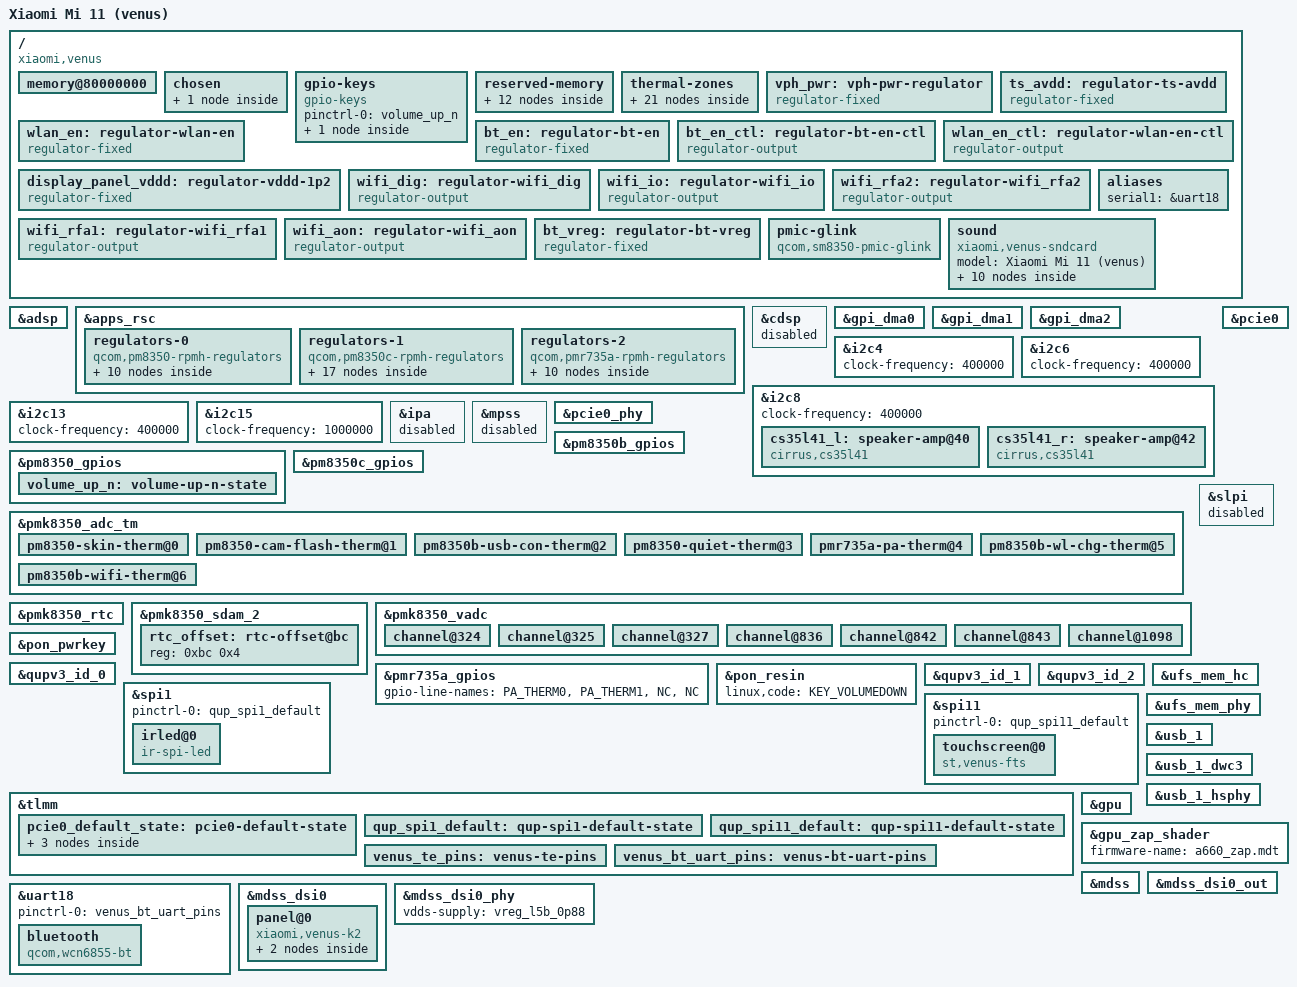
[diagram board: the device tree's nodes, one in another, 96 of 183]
// SPDX-License-Identifier: BSD-3-Clause
/*
 * Copyright (c) 2023, Xilin Wu <wuxilin123@gmail.com>
 */

/dts-v1/;

#include <dt-bindings/regulator/qcom,rpmh-regulator.h>
#include <dt-bindings/iio/qcom,spmi-adc7-pm8350.h>
#include <dt-bindings/iio/qcom,spmi-adc7-pm8350b.h>
#include <dt-bindings/iio/qcom,spmi-adc7-pmk8350.h>
#include <dt-bindings/iio/qcom,spmi-adc7-pmr735a.h>
#include "sm8350.dtsi"
#include "pm8350.dtsi"
#include "pm8350b.dtsi"
#include "pm8350c.dtsi"
#include "pmk8350.dtsi"
#include "pmr735a.dtsi"

/*
 * Delete following upstream (sm8350.dtsi) reserved
 * memory mappings which are different on this device.
 */
/delete-node/ &pil_adsp_mem;
/delete-node/ &pil_slpi_mem;
/delete-node/ &pil_cdsp_mem;
/delete-node/ &pil_ipa_fw_mem;
/delete-node/ &pil_ipa_gsi_mem;
/delete-node/ &pil_gpu_mem;
/delete-node/ &pil_spss_mem;
/delete-node/ &pil_modem_mem;
/delete-node/ &rmtfs_mem;
/delete-node/ &pil_trustedvm_mem;
/delete-node/ &removed_mem;

/ {
	model = "Xiaomi Mi 11 (venus)";
	compatible = "xiaomi,venus", "qcom,sm8350";

	/* ABL 挑表项用; 实测值来自本机 Android 的 /sys/firmware/fdt */
	qcom,msm-id = <0x19f 0x20001>, <0x1c8 0x20001>, <0x1f5 0x20001>;
	qcom,board-id = <0x10008 0x0>;
	chassis-type = "handset";

	/* 本机实测(Android /sys/firmware/fdt): 8GB */
	memory@80000000 {
		device_type = "memory";
		reg = <0x00 0x80000000 0x00 0x39700000>,
		      <0x01 0x80000000 0x01 0x00000000>,
		      <0x00 0xc0000000 0x00 0xc0000000>;
	};

	chosen {
		#address-cells = <2>;
		#size-cells = <2>;
		ranges;

		/* 复用 ABL 摆好的 splash 帧缓冲, 靠 simpledrm 把早期 dmesg/panic 打到屏幕上;
		 * 不涉及面板/DSI 驱动 */
		framebuffer0: framebuffer@e1000000 {
			compatible = "simple-framebuffer";
			reg = <0 0xe1000000 0 (1440 * 3200 * 4)>;
			width = <1440>;
			height = <3200>;
			stride = <(1440 * 4)>;
			format = "a8r8g8b8";
		};

	};

	gpio-keys {
		compatible = "gpio-keys";

		pinctrl-0 = <&volume_up_n>;
		pinctrl-names = "default";

		key-volume-up {
			label = "Volume Up";
			linux,code = <KEY_VOLUMEUP>;
			gpios = <&pm8350_gpios 6 GPIO_ACTIVE_LOW>;
			debounce-interval = <15>;
			linux,can-disable;
			wakeup-source;
		};
	};


	reserved-memory {
		/* venus 的 ABL splash 区 */
		cont_splash_mem: memory@e1000000 {
			reg = <0 0xe1000000 0 0x2300000>;
			no-map;
		};

		pil_adsp_mem: memory@86100000 {
			reg = <0 0x86100000 0 0x3900000>;
			no-map;
		};

		pil_slpi_mem: memory@89a00000 {
			reg = <0 0x89a00000 0 0x2f00000>;
			no-map;
		};

		pil_cdsp_mem: memory@8c900000 {
			reg = <0 0x8c900000 0 0x1e00000>;
			no-map;
		};

		pil_ipa_fw_mem: memory@8e700000 {
			reg = <0 0x8e700000 0 0x10000>;
			no-map;
		};

		pil_ipa_gsi_mem: memory@8e710000 {
			reg = <0 0x8e710000 0 0xa000>;
			no-map;
		};

		pil_gpu_mem: memory@8e71a000 {
			reg = <0 0x8e71a000 0 0x2000>;
			no-map;
		};

		pil_spss_mem: memory@8e800000 {
			reg = <0 0x8e800000 0 0x100000>;
			no-map;
		};

		pil_modem_mem: memory@8f000000 {
			reg = <0 0x8f000000 0 0x10000000>;
			no-map;
		};

		/* venus 的真实 ramoops 区(取自本机下游 DTB: reg=<0xa9000000 0x200000>,
		 * pmsg-size 占满整块)。声明成 console 区, panic 日志落在偏移 0,
		 * Android 的 /dev/pmsg0 正好映射到同一位置 */
		ramoops@a9000000 {
			compatible = "ramoops";
			reg = <0 0xa9000000 0 0x200000>;
			console-size = <0x200000>;
			no-map;
		};


		rmtfs_mem: memory@d6a00000 {
			compatible = "qcom,rmtfs-mem";
			reg = <0 0xd6a00000 0 0x300000>;
			no-map;

			qcom,client-id = <1>;
			qcom,vmid = <15>;
		};

		removed_mem: memory@d8800000 {
			reg = <0 0xd8800000 0 0x8800000>;
			no-map;
		};

	};

	thermal-zones {
		skin-thermal {
			polling-delay-passive = <0>;
			polling-delay = <0>;
			thermal-sensors = <&pmk8350_adc_tm 0>;

			trips {
				active-config0 {
					temperature = <125000>;
					hysteresis = <1000>;
					type = "passive";
				};
			};
		};

		flash-thermal {
			polling-delay-passive = <0>;
			polling-delay = <0>;
			thermal-sensors = <&pmk8350_adc_tm 1>;

			trips {
				active-config0 {
					temperature = <125000>;
					hysteresis = <1000>;
					type = "passive";
				};
			};
		};

		usb-con-thermal {
			polling-delay-passive = <0>;
			polling-delay = <0>;
			thermal-sensors = <&pmk8350_adc_tm 2>;

			trips {
				active-config0 {
					temperature = <125000>;
					hysteresis = <1000>;
					type = "passive";
				};
			};
		};

		quiet-thermal {
			polling-delay-passive = <0>;
			polling-delay = <0>;
			thermal-sensors = <&pmk8350_adc_tm 3>;

			trips {
				active-config0 {
					temperature = <125000>;
					hysteresis = <1000>;
					type = "passive";
				};
			};
		};

		pa-thermal {
			polling-delay-passive = <0>;
			polling-delay = <0>;
			thermal-sensors = <&pmk8350_adc_tm 4>;

			trips {
				active-config0 {
					temperature = <125000>;
					hysteresis = <1000>;
					type = "passive";
				};
			};
		};

		wl-chg-thermal {
			polling-delay-passive = <0>;
			polling-delay = <0>;
			thermal-sensors = <&pmk8350_adc_tm 5>;

			trips {
				active-config0 {
					temperature = <125000>;
					hysteresis = <1000>;
					type = "passive";
				};
			};
		};

		wifi-thermal {
			polling-delay-passive = <0>;
			polling-delay = <0>;
			thermal-sensors = <&pmk8350_adc_tm 6>;

			trips {
				active-config0 {
					temperature = <125000>;
					hysteresis = <1000>;
					type = "passive";
				};
			};
		};
	};

	vph_pwr: vph-pwr-regulator {
		compatible = "regulator-fixed";
		regulator-name = "vph_pwr";
		regulator-min-microvolt = <3700000>;
		regulator-max-microvolt = <3700000>;

		regulator-always-on;
		regulator-boot-on;
	};
};

&adsp {
	firmware-name = "qcom/sm8350/xiaomi/venus/adsp.mdt";
	status = "okay";
};

&apps_rsc {
	regulators-0 {
		compatible = "qcom,pm8350-rpmh-regulators";
		qcom,pmic-id = "b";

		vdd-s1-supply = <&vph_pwr>;
		vdd-s2-supply = <&vph_pwr>;
		vdd-s3-supply = <&vph_pwr>;
		vdd-s4-supply = <&vph_pwr>;
		vdd-s5-supply = <&vph_pwr>;
		vdd-s6-supply = <&vph_pwr>;
		vdd-s7-supply = <&vph_pwr>;
		vdd-s8-supply = <&vph_pwr>;
		vdd-s9-supply = <&vph_pwr>;
		vdd-s10-supply = <&vph_pwr>;
		vdd-s11-supply = <&vph_pwr>;
		vdd-s12-supply = <&vph_pwr>;

		vdd-l1-l4-supply = <&vreg_s11b_0p95>;
		vdd-l2-l7-supply = <&vreg_bob>;
		vdd-l3-l5-supply = <&vreg_bob>;
		vdd-l6-l9-l10-supply = <&vreg_s11b_0p95>;
		vdd-l8-supply = <&vreg_s2c_0p8>;

		vreg_s10b_1p8: smps10 {
			regulator-name = "vreg_s10b_1p8";
			regulator-min-microvolt = <1800000>;
			regulator-max-microvolt = <1800000>;
		};

		vreg_s11b_0p95: smps11 {
			regulator-name = "vreg_s11b_0p95";
			regulator-min-microvolt = <752000>;
			regulator-max-microvolt = <752000>;
		};

		vreg_s12b_1p25: smps12 {
			regulator-name = "vreg_s12b_1p25";
			regulator-min-microvolt = <1352000>;
			regulator-max-microvolt = <1352000>;
		};

		vreg_l1b_0p88: ldo1 {
			regulator-name = "vreg_l1b_0p88";
			regulator-min-microvolt = <912000>;
			regulator-max-microvolt = <920000>;
			regulator-initial-mode = <RPMH_REGULATOR_MODE_HPM>;
		};

		vreg_l2b_3p07: ldo2 {
			regulator-name = "vreg_l2b_3p07";
			regulator-min-microvolt = <3072000>;
			regulator-max-microvolt = <3072000>;
			regulator-initial-mode = <RPMH_REGULATOR_MODE_HPM>;
		};

		vreg_l3b_0p9: ldo3 {
			regulator-name = "vreg_l3b_0p9";
			regulator-min-microvolt = <904000>;
			regulator-max-microvolt = <904000>;
			regulator-initial-mode = <RPMH_REGULATOR_MODE_HPM>;
		};

		vreg_l5b_0p88: ldo5 {
			regulator-name = "vreg_l5b_0p88";
			regulator-min-microvolt = <880000>;
			regulator-max-microvolt = <888000>;
			regulator-initial-mode = <RPMH_REGULATOR_MODE_HPM>;
		};

		vreg_l6b_1p2: ldo6 {
			regulator-name = "vreg_l6b_1p2";
			regulator-min-microvolt = <1200000>;
			regulator-max-microvolt = <1208000>;
			regulator-initial-mode = <RPMH_REGULATOR_MODE_HPM>;
		};

		vreg_l7b_2p96: ldo7 {
			regulator-name = "vreg_l7b_2p96";
			regulator-min-microvolt = <2400000>;
			regulator-max-microvolt = <3008000>;
			regulator-initial-mode = <RPMH_REGULATOR_MODE_HPM>;
		};

		vreg_l9b_1p2: ldo9 {
			regulator-name = "vreg_l9b_1p2";
			regulator-min-microvolt = <1200000>;
			regulator-max-microvolt = <1200000>;
			regulator-initial-mode = <RPMH_REGULATOR_MODE_HPM>;
		};
	};

	regulators-1 {
		compatible = "qcom,pm8350c-rpmh-regulators";
		qcom,pmic-id = "c";

		vdd-s1-supply = <&vph_pwr>;
		vdd-s2-supply = <&vph_pwr>;
		vdd-s3-supply = <&vph_pwr>;
		vdd-s4-supply = <&vph_pwr>;
		vdd-s5-supply = <&vph_pwr>;
		vdd-s6-supply = <&vph_pwr>;
		vdd-s7-supply = <&vph_pwr>;
		vdd-s8-supply = <&vph_pwr>;
		vdd-s9-supply = <&vph_pwr>;
		vdd-s10-supply = <&vph_pwr>;

		vdd-l1-l12-supply = <&vreg_s1c_1p86>;
		vdd-l2-l8-supply = <&vreg_s1c_1p86>;
		vdd-l3-l4-l5-l7-l13-supply = <&vreg_bob>;
		vdd-l6-l9-l11-supply = <&vreg_bob>;
		vdd-l10-supply = <&vreg_s12b_1p25>;

		vdd-bob-supply = <&vph_pwr>;

		vreg_s1c_1p86: smps1 {
			regulator-name = "vreg_s1c_1p86";
			regulator-min-microvolt = <1904000>;
			regulator-max-microvolt = <1904000>;
		};

		vreg_s2c_0p8: smps2 {
			regulator-name = "vreg_s2c_0p8";
			regulator-min-microvolt = <640000>;
			regulator-max-microvolt = <1000000>;
		};

		vreg_s10c_1p05: smps10 {
			regulator-name = "vreg_s10c_1p05";
			regulator-min-microvolt = <1048000>;
			regulator-max-microvolt = <1128000>;
		};

		vreg_bob: bob {
			regulator-name = "vreg_bob";
			regulator-min-microvolt = <3008000>;
			regulator-max-microvolt = <3960000>;
			regulator-initial-mode = <RPMH_REGULATOR_MODE_AUTO>;
		};

		vreg_l1c_1p8: ldo1 {
			regulator-name = "vreg_l1c_1p8";
			regulator-min-microvolt = <1800000>;
			regulator-max-microvolt = <1800000>;
			regulator-initial-mode = <RPMH_REGULATOR_MODE_HPM>;
		};

		vreg_l2c_1p8: ldo2 {
			regulator-name = "vreg_l2c_1p8";
			regulator-min-microvolt = <1800000>;
			regulator-max-microvolt = <1800000>;
			regulator-initial-mode = <RPMH_REGULATOR_MODE_HPM>;
		};

		vreg_l3c_3p0: ldo3 {
			regulator-name = "vreg_l3c_3p0";
			regulator-min-microvolt = <3008000>;
			regulator-max-microvolt = <3300000>;
			regulator-initial-mode = <RPMH_REGULATOR_MODE_HPM>;
		};

		vreg_l4c_uim1: ldo4 {
			regulator-name = "vreg_l4c_uim1";
			regulator-min-microvolt = <1704000>;
			regulator-max-microvolt = <3000000>;
			regulator-initial-mode = <RPMH_REGULATOR_MODE_HPM>;
		};

		vreg_l5c_uim2: ldo5 {
			regulator-name = "vreg_l5c_uim2";
			regulator-min-microvolt = <1704000>;
			regulator-max-microvolt = <3000000>;
			regulator-initial-mode = <RPMH_REGULATOR_MODE_HPM>;
		};

		vreg_l6c_1p8: ldo6 {
			regulator-name = "vreg_l6c_1p8";
			regulator-min-microvolt = <1800000>;
			regulator-max-microvolt = <2960000>;
			regulator-initial-mode = <RPMH_REGULATOR_MODE_HPM>;
		};

		vreg_l7c_3p0: ldo7 {
			regulator-name = "vreg_l7c_3p0";
			regulator-min-microvolt = <3008000>;
			regulator-max-microvolt = <3008000>;
			regulator-initial-mode = <RPMH_REGULATOR_MODE_HPM>;
		};

		vreg_l8c_1p8: ldo8 {
			regulator-name = "vreg_l8c_1p8";
			regulator-min-microvolt = <1800000>;
			regulator-max-microvolt = <1800000>;
			regulator-initial-mode = <RPMH_REGULATOR_MODE_HPM>;
		};

		vreg_l9c_2p96: ldo9 {
			regulator-name = "vreg_l9c_2p96";
			regulator-min-microvolt = <2960000>;
			regulator-max-microvolt = <3008000>;
			regulator-initial-mode = <RPMH_REGULATOR_MODE_HPM>;
		};

		vreg_l10c_1p2: ldo10 {
			regulator-name = "vreg_l10c_1p2";
			regulator-min-microvolt = <1200000>;
			regulator-max-microvolt = <1200000>;
			regulator-initial-mode = <RPMH_REGULATOR_MODE_HPM>;
		};

		vreg_l11c_2p96: ldo11 {
			regulator-name = "vreg_l11c_2p96";
			regulator-min-microvolt = <2400000>;
			regulator-max-microvolt = <3008000>;
			regulator-initial-mode = <RPMH_REGULATOR_MODE_HPM>;
		};

		vreg_l12c_1p8: ldo12 {
			regulator-name = "vreg_l12c_1p8";
			regulator-min-microvolt = <1800000>;
			regulator-max-microvolt = <2000000>;
			regulator-initial-mode = <RPMH_REGULATOR_MODE_HPM>;
		};

		vreg_l13c_3p0: ldo13 {
			regulator-name = "vreg_l13c_3p0";
			regulator-min-microvolt = <3000000>;
			regulator-max-microvolt = <3000000>;
			regulator-initial-mode = <RPMH_REGULATOR_MODE_HPM>;
		};
	};

	regulators-2 {
		compatible = "qcom,pmr735a-rpmh-regulators";
		qcom,pmic-id = "e";

		vdd-s1-supply = <&vph_pwr>;
		vdd-s2-supply = <&vph_pwr>;
		vdd-s3-supply = <&vph_pwr>;

		vdd-l1-l2-supply = <&pmr735a_s2>;
		vdd-l3-supply = <&pmr735a_s1>;
		vdd-l4-supply = <&vreg_s1c_1p86>;
		vdd-l5-l6-supply = <&vreg_s1c_1p86>;
		vdd-l7-bob-supply = <&vreg_bob>;

		pmr735a_s1: smps1 {
			regulator-name = "pmr735a_s1";
			regulator-min-microvolt = <1200000>;
			regulator-max-microvolt = <1280000>;
		};

		pmr735a_s2: smps2 {
			regulator-name = "pmr735a_s2";
			regulator-min-microvolt = <500000>;
			regulator-max-microvolt = <976000>;
		};

		pmr735a_s3: smps3 {
			regulator-name = "pmr735a_s3";
			regulator-min-microvolt = <2200000>;
			regulator-max-microvolt = <2352000>;
		};

		pmr735a_l1: ldo1 {
			regulator-name = "pmr735a_l1";
			regulator-min-microvolt = <912000>;
			regulator-max-microvolt = <912000>;
		};

		pmr735a_l2: ldo2 {
			regulator-name = "pmr735a_l2";
			regulator-min-microvolt = <1200000>;
			regulator-max-microvolt = <1200000>;
		};

		pmr735a_l3: ldo3 {
			regulator-name = "pmr735a_l3";
			regulator-min-microvolt = <1200000>;
			regulator-max-microvolt = <1200000>;
		};

		pmr735a_l4: ldo4 {
			regulator-name = "pmr735a_l4";
			regulator-min-microvolt = <1776000>;
			regulator-max-microvolt = <1872000>;
		};

		pmr735a_l5: ldo5 {
			regulator-name = "pmr735a_l5";
			regulator-min-microvolt = <800000>;
			regulator-max-microvolt = <800000>;
		};

		pmr735a_l6: ldo6 {
			regulator-name = "pmr735a_l6";
			regulator-min-microvolt = <480000>;
			regulator-max-microvolt = <904000>;
		};

		pmr735a_l7: ldo7 {
			regulator-name = "pmr735a_l7";
			regulator-min-microvolt = <2800000>;
			regulator-max-microvolt = <2800000>;
			regulator-always-on;
		};
	};
};

&cdsp {
	firmware-name = "qcom/sm8350/xiaomi/venus/cdsp.mbn";
	status = "okay";
};

&gpi_dma0 {
	status = "okay";
};

&gpi_dma1 {
	status = "okay";
};

&gpi_dma2 {
	status = "okay";
};

&i2c4 {
	clock-frequency = <400000>;
	status = "okay";

	/* Zinitix BT541 or Cypress CYTTSP5 rear touchscreen @ 24 */
};

&i2c6 {
	clock-frequency = <400000>;
	status = "okay";

	/* AWINIC AW8697 vibrator @ 5a */
};

&i2c8 {
	clock-frequency = <400000>;
	status = "okay";

	cs35l41_l: speaker-amp@40 {
		compatible = "cirrus,cs35l41";
		reg = <0x40>;
		interrupt-parent = <&tlmm>;
		interrupts = <44 IRQ_TYPE_LEVEL_LOW>;
		reset-gpios = <&tlmm 15 GPIO_ACTIVE_HIGH>;
		VA-supply = <&vreg_s10b_1p8>;
		VP-supply = <&vph_pwr>;
		cirrus,boost-peak-milliamp = <4000>;
		cirrus,boost-ind-nanohenry = <1000>;
		cirrus,boost-cap-microfarad = <15>;
		cirrus,gpio2-src-select = <2>;
		cirrus,gpio2-output-enable;
		cirrus,asp-sdout-hiz = <3>;
		#sound-dai-cells = <1>;
		sound-name-prefix = "SPK-L";
	};

	cs35l41_r: speaker-amp@42 {
		compatible = "cirrus,cs35l41";
		reg = <0x42>;
		interrupt-parent = <&tlmm>;
		interrupts = <116 IRQ_TYPE_LEVEL_LOW>;
		reset-gpios = <&tlmm 42 GPIO_ACTIVE_HIGH>;
		VA-supply = <&vreg_s10b_1p8>;
		VP-supply = <&vph_pwr>;
		cirrus,boost-peak-milliamp = <4000>;
		cirrus,boost-ind-nanohenry = <1000>;
		cirrus,boost-cap-microfarad = <15>;
		cirrus,gpio2-src-select = <2>;
		cirrus,gpio2-output-enable;
		cirrus,asp-sdout-hiz = <3>;
		#sound-dai-cells = <1>;
		sound-name-prefix = "SPK-R";
	};
};

&i2c13 {
	clock-frequency = <400000>;
	status = "okay";

};

&i2c15 {
	clock-frequency = <1000000>;
	status = "okay";
};

&ipa {
	qcom,gsi-loader = "self";
	memory-region = <&pil_ipa_fw_mem>;
	firmware-name = "qcom/sm8350/xiaomi/venus/ipa_fws.mbn";
	status = "okay";
};

&mpss {
	firmware-name = "qcom/sm8350/xiaomi/venus/modem.mbn";
	status = "okay";
};

&pcie0 {
	pinctrl-names = "default";
	pinctrl-0 = <&pcie0_default_state>;

	perst-gpios = <&tlmm 94 GPIO_ACTIVE_LOW>;
	wake-gpios = <&tlmm 96 GPIO_ACTIVE_HIGH>;

	status = "okay";
};

&pcie0_phy {
	vdda-phy-supply = <&vreg_l5b_0p88>;
	vdda-pll-supply = <&vreg_l6b_1p2>;

	status = "okay";
};

&pm8350_gpios {
	gpio-line-names = "NC",
			  "BuildID",
			  "NC",
			  "ProjectID",
			  "NC",
			  "KEY_VOLP_N",
			  "SP_ARI_POWER_ALARM",
			  "NC",
			  "NC",
			  "GND";

	volume_up_n: volume-up-n-state {
		pins = "gpio6";
		function = "normal";
		power-source = <1>;
		bias-pull-up;
		input-enable;
	};
};

&pm8350b_gpios {
	gpio-line-names = "WIFI_THERM",
			  "WP_THERM",
			  "NC",
			  "NC",
			  "NC",
			  "FORCED_USB_BOOT",
			  "NC",
			  "NC";
};

&pm8350c_gpios {
	gpio-line-names = "VDD_BOOST_5V_EN",
			  "NC",
			  "OTG_OVP_EN",
			  "WL_TXON",
			  "NC",
			  "NC",
			  "NC",
			  "NC",
			  "NC";
};

&pmk8350_adc_tm {
	status = "okay";

	pm8350-skin-therm@0 {
		reg = <0>;
		io-channels = <&pmk8350_vadc PM8350_ADC7_AMUX_THM1_100K_PU(1)>;
		qcom,ratiometric;
		qcom,hw-settle-time-us = <200>;
	};

	pm8350-cam-flash-therm@1 {
		reg = <1>;
		io-channels = <&pmk8350_vadc PM8350_ADC7_AMUX_THM2_100K_PU(1)>;
		qcom,ratiometric;
		qcom,hw-settle-time-us = <200>;
	};

	pm8350b-usb-con-therm@2 {
		reg = <2>;
		io-channels = <&pmk8350_vadc PM8350B_ADC7_AMUX_THM1_100K_PU>;
		qcom,ratiometric;
		qcom,hw-settle-time-us = <200>;
	};

	pm8350-quiet-therm@3 {
		reg = <3>;
		io-channels = <&pmk8350_vadc PM8350_ADC7_AMUX_THM4_100K_PU(1)>;
		qcom,ratiometric;
		qcom,hw-settle-time-us = <200>;
	};

	pmr735a-pa-therm@4 {
		reg = <4>;
		io-channels = <&pmk8350_vadc PMR735A_ADC7_GPIO1_100K_PU>;
		qcom,ratiometric;
		qcom,hw-settle-time-us = <200>;
	};

	pm8350b-wl-chg-therm@5 {
		reg = <5>;
		io-channels = <&pmk8350_vadc PM8350B_ADC7_GPIO2_100K_PU>;
		qcom,ratiometric;
		qcom,hw-settle-time-us = <200>;
	};

	pm8350b-wifi-therm@6 {
		reg = <6>;
		io-channels = <&pmk8350_vadc PM8350B_ADC7_GPIO1_100K_PU>;
		qcom,ratiometric;
		qcom,hw-settle-time-us = <200>;
	};
};

&pmk8350_rtc {
	nvmem-cells = <&rtc_offset>;
	nvmem-cell-names = "offset";

	status = "okay";
};

&pmk8350_sdam_2 {
	status = "okay";

	rtc_offset: rtc-offset@bc {
		reg = <0xbc 0x4>;
	};
};

&pmk8350_vadc {
	channel@324 {
		reg = <PM8350_ADC7_AMUX_THM1_100K_PU(1)>;
		qcom,ratiometric;
		qcom,hw-settle-time = <200>;
		qcom,pre-scaling = <1 1>;
		label = "pm8350_skin_therm";
	};

	channel@325 {
		reg = <PM8350_ADC7_AMUX_THM2_100K_PU(1)>;
		qcom,ratiometric;
		qcom,hw-settle-time = <200>;
		qcom,pre-scaling = <1 1>;
		label = "pm8350_cam_flash_therm";
	};

	channel@327 {
		reg = <PM8350_ADC7_AMUX_THM4_100K_PU(1)>;
		qcom,ratiometric;
		qcom,hw-settle-time = <200>;
		qcom,pre-scaling = <1 1>;
		label = "pm8350_quiet_therm";
	};

	channel@836 {
		reg = <PM8350B_ADC7_AMUX_THM1_100K_PU>;
		qcom,ratiometric;
		qcom,hw-settle-time = <200>;
		qcom,pre-scaling = <1 1>;
		label = "pm8350b_usb_con_therm";
	};

	channel@842 {
		reg = <PM8350B_ADC7_GPIO1_100K_PU>;
		qcom,ratiometric;
		qcom,hw-settle-time = <200>;
		qcom,pre-scaling = <1 1>;
		label = "pm8350b_wifi_therm";
	};

	channel@843 {
		reg = <PM8350B_ADC7_GPIO2_100K_PU>;
		qcom,ratiometric;
		qcom,hw-settle-time = <200>;
		qcom,pre-scaling = <1 1>;
		label = "pm8350b_wl_chg_therm";
	};

	channel@1098 {
		reg = <PMR735A_ADC7_GPIO1_100K_PU>;
		qcom,ratiometric;
		qcom,hw-settle-time = <200>;
		qcom,pre-scaling = <1 1>;
		label = "pmr735a_pa_therm";
	};
};

&pmr735a_gpios {
	gpio-line-names = "PA_THERM0",
			  "PA_THERM1",
			  "NC",
			  "NC";
};

&pon_pwrkey {
	status = "okay";
};

&pon_resin {
	linux,code = <KEY_VOLUMEDOWN>;
	status = "okay";
};

&qupv3_id_0 {
	status = "okay";
};

&qupv3_id_1 {
	status = "okay";
};

&qupv3_id_2 {
	status = "okay";
};

&slpi {
	firmware-name = "qcom/sm8350/xiaomi/venus/slpi.mbn";
	status = "okay";
};

&spi1 {
	pinctrl-names = "default";
	pinctrl-0 = <&qup_spi1_default>;
	status = "okay";

	irled@0 {
		compatible = "ir-spi-led";
		reg = <0>;
		power-supply = <&vph_pwr>;
		spi-max-frequency = <19200000>;
	};
};

/*
 * 触摸 AVDD 开关：厂商把 PM8350C L3C 的 3.3V 经 GPIO132 负载开关送给触摸控制器。
 * 缺这一步芯片不上电（表现为 SPI 读回全 0、chip_id=0x0000）。
 */
/ {
	ts_avdd: regulator-ts-avdd {
		compatible = "regulator-fixed";
		regulator-name = "ts_avdd";
		regulator-min-microvolt = <3300000>;
		regulator-max-microvolt = <3300000>;
		vin-supply = <&vreg_l3c_3p0>;
		gpio = <&tlmm 132 GPIO_ACTIVE_HIGH>;
		enable-active-high;
		startup-delay-us = <4000>;
	};
};

&spi11 {
	pinctrl-names = "default";
	pinctrl-0 = <&qup_spi11_default>;
	status = "okay";

	/*
	 * STM FTS 触摸（SE11）。本步只加这一个子节点：两路电都直接引用 PMIC LDO
	 * （vdd = L2C 1.8V，avdd = L3C 3.0~3.3V），不引入 GPIO132 负载开关、
	 * 也不改 L3C 的电压上限 —— 上一次把这三样一起加进来直接挂机了。
	 */
	touchscreen@0 {
		compatible = "st,venus-fts";
		reg = <0>;
		spi-max-frequency = <7000000>;
		interrupt-parent = <&tlmm>;
		interrupts = <23 IRQ_TYPE_LEVEL_LOW>;
		reset-gpios = <&tlmm 22 GPIO_ACTIVE_LOW>;
		vdd-supply = <&vreg_l2c_1p8>;
		avdd-supply = <&ts_avdd>;
	};
};

&tlmm {
	gpio-reserved-ranges = <52 8>;
	gpio-line-names = "APPS_I2C_SDA", /* GPIO_0 */
			  "APPS_I2C_SCL",
			  "FSA_INT_N",
			  "SEC_AMOLED_CVO_EN",
			  "WLC_PMIC_I2C_SDA",
			  "WLC_PMIC_I2C_SCL",
			  "SBU_UART_EN",
			  "WLC_INT_N",
			  "NC",
			  "INFARED_SPI_MOSI",
			  "NC", /* GPIO_10 */
			  "NC",
			  "CAMW_AVDD_EN",
			  "AMOLED_VDDI_EN",
			  "CP_INT",
			  "SMART_PA_0_EN",
			  "CAM1_RESET_N",
			  "CAM5_RESET_N",
			  "DEBUG_UART_TX",
			  "DEBUG_UART_RX",
			  "TS_I2C_SDA", /* GPIO_20 */
			  "TS_I2C_SCL",
			  "TP_RESET_N",
			  "TP_INT_N",
			  "LCD_RESET_N",
			  "WL_CP_EN_AP",
			  "WL_DET",
			  "CP_INT_S",
			  "HAP_I2C_SDA",
			  "HAP_I2C_SCL",
			  "SEC_AMOLED_RESET_DIS", /* GPIO_30 */
			  "SEC_AMOLED_TP_INT",
			  "PM8008_1_IRQ",
			  "PM8008_1_RESET_N",
			  "CAMFD_AVDD_EN",
			  "SEC_AMOLED_VDDI_EN",
			  "SPKR_I2C_SDA",
			  "SPKR_I2C_SCL",
			  "FOD_INT_N1",
			  "FOD_RST",
			  "SMB_SPMI_DATA", /* GPIO_40 */
			  "SMB_SPMI_CLK",
			  "WLS_CHARGE_CTRL",
			  "FORCED_USB_BOOT",
			  "SPKR_INT",
			  "LCD_ID_DET1",
			  "CHARGER_UART_TX",
			  "CHARGER_UART_RX",
			  "TP_SPI_MISO",
			  "TP_SPI_MOSI",
			  "TP_SPI_CLK", /* GPIO_50 */
			  "TP_SPI_CS",
			  "FOD_SPI_MISO",
			  "FOD_SPI_MOSI",
			  "FOD_SPI_CLK",
			  "FOD_SPI_CS",
			  "NFC_SE_SPI_MISO",
			  "NFC_SE_SPI_MOSI",
			  "NFC_SE_SPI_CLK",
			  "NFC_SE_SPI_CS",
			  "NFC_I2C_SDA", /* GPIO_60 */
			  "NFC_I2C_SCL",
			  "NFC_EN",
			  "NFC_CLK_REQ",
			  "HST_WLAN_EN",
			  "HST_BT_EN",
			  "CAMU_AVDD_EN",
			  "VBUS_NTC_CTRL",
			  "HST_BT_UART_CTS",
			  "HST_BT_UART_RFR",
			  "HST_BT_UART_TX", /* GPIO_70 */
			  "HST_BT_UART_RX",
			  "ADSP_FG_I2C_SDA",
			  "ADSP_FG_I2C_SCL",
			  "DISP_RATE",
			  "ERR_INT_N",
			  "TOF_SPI_MISO",
			  "TOF_SPI_MOSI",
			  "TOF_SPI_CLK",
			  "TOF_SPI_CS",
			  "HALL_OUT1", /* GPIO_80 */
			  "USB_CC_DIR",
			  "MDP_VSYNC_P",
			  "SEC_AMOLED_TE_DIS",
			  "FLICKER_INT",
			  "HALL_OUT2",
			  "NFC_DWL_REQ",
			  "NFC_INT_REQ",
			  "WCD_RESET_N",
			  "ALS_INT_N",
			  "GPIO_BQ25970_MASTER_INT", /* GPIO_90 */
			  "GYRO_INT",
			  "NC",
			  "CAMF_DVDD_EN",
			  "PCIE0_RESET_N",
			  "PCIE0_CLK_REQ_N",
			  "PCIE0_WAKE_N",
			  "RF_CABLE_INT2",
			  "NC",
			  "TOF_IRQ",
			  "CAM_MCLK0", /* GPIO_100 */
			  "CAM_MCLK1",
			  "CAM_MCLK2",
			  "CAM_MCLK3",
			  "NC",
			  "CAM_MCLK5",
			  "CAM3_RESET_N",
			  "CCI_I2C0_SDA",
			  "CCI_I2C0_SCL",
			  "CCI_I2C1_SDA",
			  "CCI_I2C1_SCL", /* GPIO_110 */
			  "CCI_I2C2_SDA",
			  "CCI_I2C2_SCL",
			  "CCI_I2C3_SDA",
			  "CCI_I2C3_SCL",
			  "SEC_AMOLED_TP_3P3_EN",
			  "SPKR_PA_INT",
			  "CAM2_RESET_N",
			  "ACCEL_INT",
			  "HAP_DRV_INT",
			  "SPKR_I2S_BCK", /* GPIO_120 */
			  "SPKR_I2S_DIN",
			  "SPKR_I2S_WS",
			  "GPIO_BQ25970_SLAVE_INT",
			  "SPKR_I2S_DOUT",
			  "SEC_AMOLED_TP_RST",
			  "RF_CABLE_INT1",
			  "WLS_QUCK_EN",
			  "NC",
			  "HST_BT_WLAN_SLIMBUS_CLK",
			  "HST_BT_WLAN_SLIMBUS_DAT0", /* GPIO_130 */
			  "NC",
			  "TP_3P3_EN",
			  "UIM2_DATA",
			  "UIM2_CLK",
			  "UIM2_RESET",
			  "UIM2_PRESENT",
			  "UIM1_DATA",
			  "UIM1_CLK",
			  "UIM1_RESET",
			  "UIM1_PRESENT", /* GPIO_140 */
			  "SM_RFFE0_CLK",
			  "SM_RFFE0_DATA",
			  "SM_RFFE1_CLK",
			  "SM_RFFE1_DATA",
			  "SM_RFFE2_CLK",
			  "SM_RFFE2_DATA",
			  "SM_RFFE3_CLK",
			  "SM_RFFE3_DATA",
			  "SM_RFFE4_CLK",
			  "SM_RFFE4_DATA", /* GPIO_150 */
			  "WLAN_COEX_UART1_RX",
			  "WLAN_COEX_UART1_TX",
			  "HST_SW_CTRL",
			  "SEC_AMOLED_VDDI_TP_EN",
			  "HAP_DRV_RSTN",
			  "NC",
			  "NC",
			  "NC",
			  "QLINK0_REQ",
			  "QLINK0_EN", /* GPIO_160 */
			  "QLINK0_WMSS_RESET_N",
			  "NC",
			  "NC",
			  "NC",
			  "NC",
			  "RF_CABLE_INT3",
			  "NC",
			  "WCD_SWR_TX_CLK",
			  "WCD_SWR_TX_DATA0",
			  "WCD_SWR_TX_DATA1", /* GPIO_170 */
			  "HAP_SWR_RX_CLK",
			  "HAP_SWR_RX_DATA0",
			  "WCD_SWR_RX_DATA1",
			  "NC",
			  "CAMW_DVDD_EN",
			  "NC",
			  "NC",
			  "NC",
			  "NC",
			  "NC", /* GPIO_180 */
			  "NC",
			  "WCD_SWR_TX_DATA2",
			  "ACC_I3C_SDA",
			  "ACC_I3C_SCL",
			  "SSC_SENSOR_I2C1_SDA",
			  "SSC_SENSOR_I2C1_SCL",
			  "NC",
			  "TCS3718_GPIO",
			  "NC",
			  "NC", /* GPIO_190 */
			  "SSC_MAG_I2C_SDA",
			  "SSC_MAG_I2C_SCL",
			  "SSC_SENSOR_I2C_SDA",
			  "SSC_SENSOR_I2C_SCL",
			  "NC",
			  "NC",
			  "NC",
			  "NC",
			  "HST_BLE_UART_TX",
			  "HST_BLE_UART_RX", /* GPIO_200 */
			  "HST_WLAN_UART_TX",
			  "HST_WLAN_UART_RX";

	pcie0_default_state: pcie0-default-state {
		perst-pins {
			pins = "gpio94";
			function = "gpio";
			drive-strength = <2>;
			bias-pull-down;
		};

		clkreq-pins {
			pins = "gpio95";
			function = "pcie0_clkreqn";
			drive-strength = <2>;
			bias-pull-up;
		};

		wake-pins {
			pins = "gpio96";
			function = "gpio";
			drive-strength = <2>;
			bias-pull-up;
		};
	};

	qup_spi1_default: qup-spi1-default-state {
		pins = "gpio8", "gpio9", "gpio10", "gpio11";
		function = "qup1";
		drive-strength = <6>;
		bias-disable;
	};

	qup_spi11_default: qup-spi11-default-state {
		pins = "gpio48", "gpio49", "gpio50", "gpio51";
		function = "qup11";
		drive-strength = <6>;
		bias-disable;
	};
};

&ufs_mem_hc {
	reset-gpios = <&tlmm 203 GPIO_ACTIVE_LOW>;
	vcc-supply = <&vreg_l7b_2p96>;
	vcc-max-microamp = <800000>;
	vccq-supply = <&vreg_l9b_1p2>;
	vccq-max-microamp = <900000>;
	vdd-hba-supply = <&vreg_l9b_1p2>;

	status = "okay";
};

&ufs_mem_phy {
	vdda-phy-supply = <&vreg_l5b_0p88>;
	vdda-pll-supply = <&vreg_l6b_1p2>;

	status = "okay";
};

&usb_1 {
	/* 父节点也只保留 USB2 PHY, 否则 dwc3 会一直 deferred 等 disabled 的 QMP PHY */
	phys = <&usb_1_hsphy>;
	phy-names = "usb2-phy";

	/* USB 2.0 only */
	qcom,select-utmi-as-pipe-clk;
	status = "okay";
};

&usb_1_dwc3 {
	dr_mode = "peripheral";
	maximum-speed = "high-speed";
	/* Remove USB3 phy */
	phys = <&usb_1_hsphy>;
	phy-names = "usb2-phy";
};


&usb_1_hsphy {
	/* venus 厂商值: xiaomi-sm8350-common.dtsi 的 &usb2_phy0 param-override-seq */
	qcom,param-override-seq = <0xc6 0x6c 0x0f 0x70 0x00 0x74>;

	vdda-pll-supply = <&vreg_l5b_0p88>;
	vdda18-supply = <&vreg_l1c_1p8>;
	vdda33-supply = <&vreg_l2b_3p07>;

	status = "okay";
};

/* ---- WiFi(qca6490): 下游 DTB 实测 wlan-en-gpio = tlmm 64(高有效),
 *      bt-en = 65, sw-ctrl = 153; 电源来自 PMIC 各路(S10/S11/L9/PMR735A 等) ---- */
/ {
	wlan_en: regulator-wlan-en {
		compatible = "regulator-fixed";
		regulator-name = "wlan_en";
		regulator-min-microvolt = <1800000>;
		regulator-max-microvolt = <1800000>;
		gpio = <&tlmm 64 GPIO_ACTIVE_HIGH>;
		enable-active-high;
		regulator-boot-on;
		startup-delay-us = <200000>;
	};

};

/* ---- GPU: Adreno 660 ---- */
&gpu {
	status = "okay";
};

&gpu_zap_shader {
	firmware-name = "a660_zap.mdt";
};

/* ---- 蓝牙: WCN6851 on uart18 ---- */
&qupv3_id_2 {
	status = "okay";
};

&tlmm {
	/*
	 * 面板 TE（ tearing effect ）是**物理引脚**：厂商 DTB 里
	 * qcom,platform-te-gpio = <&tlmm 0x52 0>，即 gpio82。
	 * 把它复用到 mdp_vsync 硬件功能，DPU 的 vsync GPIO_0 才能收到真实 TE，
	 * 命令模式面板的 tearcheck 才有真节奏（不再用定时器猜）。
	 * 参数参照同类主线机型（qcm6490-fairphone-fp5 / sdm845-blueline）。
	 */
	venus_te_pins: venus-te-pins {
		pins = "gpio82";
		function = "mdp_vsync";
		drive-strength = <2>;
		bias-pull-down;
	};

	venus_bt_uart_pins: venus-bt-uart-pins {
		pins = "gpio68", "gpio69", "gpio70", "gpio71";
		function = "qup18";
		drive-strength = <2>;
		bias-disable;
	};
};

&uart18 {
	status = "okay";
	pinctrl-names = "default";
	pinctrl-0 = <&venus_bt_uart_pins>;

	bluetooth {
		compatible = "qcom,wcn6855-bt";

		/* 厂商 DTB 实证：bt-reset-gpio = tlmm 65、bt-sw-ctrl-gpio = tlmm 153。
		 * GPIO65 只由 hci_qca 通过 enable-gpios 驱动（复位脉冲 + 读 SW_CTRL）。
		 * 注意：不能再给 65 号脚套一个 regulator-fixed，否则两个 owner 互相
		 * 覆盖，芯片拿不到干净的复位脉冲 → ROM 版本读取 0xfc00 一直超时。 */
		enable-gpios = <&tlmm 65 GPIO_ACTIVE_HIGH>;
		swctrl-gpios = <&tlmm 153 GPIO_ACTIVE_HIGH>;

		/*
		 * 芯片自报的 BD_ADDR 是全零（00:00:00:00:5A:AD），内核据此把设备标成
		 * HCI_UNCONFIGURED → hciconfig up 直接 -EOPNOTSUPP，BlueZ 也看不到控制器。
		 * 给一个固定的本地地址即可（格式是小端字节序）。
		 */
		local-bd-address = [5f 4d 3c 22 11 02];
		/* 电源轨已由 venus-wifi-power 在运行时打开(wlan/bt 共用),
		 * 这里挂一个 always-on 的 fixed 稳压器满足驱动的 bulk_get */
		vddio-supply = <&bt_vreg>;
		vddbtcxmx-supply = <&bt_vreg>;
		vddrfacmn-supply = <&bt_vreg>;
		vddrfa0p8-supply = <&bt_vreg>;
		vddrfa1p7-supply = <&bt_vreg>;
		vddrfa1p2-supply = <&bt_vreg>;
	};
};

/* ---- wlan_en / bt_en 的运行时开关(套一层 regulator-output 才有可写 state) ---- */
/ {
	/*
	 * BT_EN（gpio65）由这个 fixed regulator 在开机就拉高。
	 * 关键：只有它在时，hci_qca 才不会在 1.6s 的 probe 阶段就去做固件下载
	 * （那时 preinit 还没把 firmware_class.path 指向 /run/current-system/firmware，
	 *  必然 -2 失败并把芯片留在坏状态）；上电/固件下载会推迟到 open，届时路径已就绪。
	 */
	bt_en: regulator-bt-en {
		compatible = "regulator-fixed";
		regulator-name = "bt_en";
		regulator-min-microvolt = <1800000>;
		regulator-max-microvolt = <1800000>;
		gpio = <&tlmm 65 GPIO_ACTIVE_HIGH>;
		enable-active-high;
		regulator-boot-on;
	};

	bt_en_ctl: regulator-bt-en-ctl {
		compatible = "regulator-output";
		regulator-name = "bt_en_ctl";
		vout-supply = <&bt_en>;
		regulator-boot-on;
	};

	wlan_en_ctl: regulator-wlan-en-ctl {
		compatible = "regulator-output";
		regulator-name = "wlan_en_ctl";
		vout-supply = <&wlan_en>;
		regulator-boot-on;
	};

};

/* ---- 显示: mdss / dsi0 / dsi0_phy / 面板 ---- */
/* 面板 1.2V 逻辑电源：厂商 DTS 里由 GPIO83 使能（display_panel_vddd） */
/ {
	display_panel_vddd: regulator-vddd-1p2 {
		compatible = "regulator-fixed";
		regulator-name = "vddd_1p2";
		regulator-min-microvolt = <1200000>;
		regulator-max-microvolt = <1200000>;
		gpio = <&tlmm 83 GPIO_ACTIVE_HIGH>;
		enable-active-high;
		regulator-always-on;
	};
};
&mdss {
	status = "okay";
};

&mdss_dsi0 {
	vdda-supply = <&vreg_l6b_1p2>;

	/* dsi_host.c 在 dsi_host_init 里 pinctrl_pm_select_default_state()，
	 * 所以 TE 引脚的复用要挂在这里（不是面板节点，面板驱动不处理 pinctrl）。 */
	pinctrl-names = "default";
	pinctrl-0 = <&venus_te_pins>;

	status = "okay";
};

&mdss_dsi0_phy {
	vdds-supply = <&vreg_l5b_0p88>;
	status = "okay";
};

&mdss_dsi0_out {
	remote-endpoint = <&venus_panel_in>;
	data-lanes = <0 1 2 3>;
	/*
	 * 命令模式面板的 vsync 源。面板的 TE 接在 tlmm gpio82，已复用到 mdp_vsync
	 * 硬件功能（见 venus_te_pins），对应 DPU 的 vsync GPIO_0 → "mdp_vsync_p"。
	 * （dpu_kms.c 里 te-source 缺省就是 GPIO_0；同类机型 qcm6490-fairphone-fp5
	 *   只做引脚复用、不写 te-source。）
	 */
	qcom,te-source = "mdp_vsync_p";
};

&mdss_dsi0 {
	panel@0 {
		compatible = "xiaomi,venus-k2";
		reg = <0>;

		reset-gpios = <&tlmm 24 GPIO_ACTIVE_LOW>;

		vddio-supply = <&vreg_l12c_1p8>;
		vdd-supply = <&vreg_l13c_3p0>;
		vddd-supply = <&display_panel_vddd>;

		port {
			venus_panel_in: endpoint {
				remote-endpoint = <&mdss_dsi0_out>;
			};
		};
	};
};

/* ---- WiFi 电源: 运行时开关(regulator-userspace-consumer) ---- */
/ {
	wifi_dig: regulator-wifi_dig {
		compatible = "regulator-output";
		regulator-name = "wifi_dig";
		vout-supply = <&vreg_s11b_0p95>;
		regulator-boot-on;
	};

	wifi_io: regulator-wifi_io {
		compatible = "regulator-output";
		regulator-name = "wifi_io";
		vout-supply = <&vreg_s10b_1p8>;
		regulator-boot-on;
	};

	wifi_rfa2: regulator-wifi_rfa2 {
		compatible = "regulator-output";
		regulator-name = "wifi_rfa2";
		vout-supply = <&vreg_s12b_1p25>;
		regulator-boot-on;
	};

	wifi_rfa1: regulator-wifi_rfa1 {
		compatible = "regulator-output";
		regulator-name = "wifi_rfa1";
		vout-supply = <&vreg_s1c_1p86>;
		regulator-boot-on;
	};

	wifi_aon: regulator-wifi_aon {
		compatible = "regulator-output";
		regulator-name = "wifi_aon";
		vout-supply = <&pmr735a_s2>;
		regulator-boot-on;
	};

	bt_vreg: regulator-bt-vreg {
		compatible = "regulator-fixed";
		regulator-name = "bt_vreg";
		regulator-min-microvolt = <1800000>;
		regulator-max-microvolt = <1800000>;
		regulator-always-on;
	};
};

/* ---- 阶段2: 只保留 UFS/USB2/稳压器/tlmm/串口/屏幕日志, 其余逐步再开 ---- */
&cdsp { status = "disabled"; };
&mpss { status = "disabled"; };
&slpi { status = "disabled"; };
&ipa { status = "disabled"; };

/*
 * qcom_geni_serial 需要 aliases 里的 serialN 才能拿到 line 号；
 * 没有它 probe 报 "Invalid line -19"，UART 不注册，其下的 bluetooth 子节点
 * （qcom,wcn6855-bt）也就不会生成 serdev → 没有 hci0。
 */
/ {
	aliases {
		serial1 = &uart18;
	};
};

/*
 * 电池/充电的官方通道：ADSP 上的 PMIC GLINK 服务。
 * pmic_glink 会创建 aux 设备 "battmgr"，由 BATTERY_QCOM_BATTMGR 提供
 * /sys/class/power_supply 里的电池与充电控制（对齐 sm8350-hdk）。
 * 它需要 PDR 服务 "msm/adsp/charger_pd"，所以 ADSP remoteproc 必须先起来。
 */
/ {
	pmic-glink {
		compatible = "qcom,sm8350-pmic-glink", "qcom,pmic-glink";
	#address-cells = <1>;
	#size-cells = <0>;
	};
};

/* ---- 声卡：QDSP6 TERT TDM RX0/RX1 → 两颗 CS35L41（扬声器）---- */
/ {
	sound {
		compatible = "xiaomi,venus-sndcard";
		model = "Xiaomi Mi 11 (venus)";

		mm1-dai-link {
			link-name = "MultiMedia1";
			cpu {
				sound-dai = <&q6asmdai MSM_FRONTEND_DAI_MULTIMEDIA1>;
			};
		};

		tdm0-dai-link {
			link-name = "Tertiary TDM0 Playback";
			cpu {
				sound-dai = <&q6afedai TERTIARY_TDM_RX_0>;
			};
			platform {
				sound-dai = <&q6routing>;
			};
			codec {
				sound-dai = <&cs35l41_l 0>;
			};
		};

		tdm1-dai-link {
			link-name = "Tertiary TDM1 Playback";
			cpu {
				sound-dai = <&q6afedai TERTIARY_TDM_RX_1>;
			};
			platform {
				sound-dai = <&q6routing>;
			};
			codec {
				sound-dai = <&cs35l41_r 0>;
			};
		};
	};
};
